# N32G032 register map
Vendor: Nationstech Ltd.; File version: 1.0
Registers are 32-bit, read-write, reset 0x0 unless marked. A register's access mark holds for its fields unless they carry their own. Offsets are from the block's base; [hi:lo] are bit positions; {n}, {i} and the like mark numbered series.

## EXTI — external interrupt/event controller
Base 0x40010400
0x00 EXTI_IMASK
  [23:0] IMASK
0x04 EXTI_EMASK
  [23:0] EMASK
0x08 EXTI_RT_CFG
  [23:0] RT_CFG
0x0C EXTI_FT_CFG
  [23:0] FT_CFG
0x10 EXTI_SWIE
  [23:0] SWIE
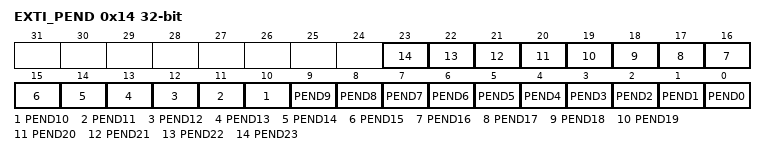
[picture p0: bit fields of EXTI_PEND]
0x14 EXTI_PEND
  [n] PEND{n} (n=0..23)
0x18 EXTI_TS_SEL
  [3:0] TSSEL

## FLASH — interal FLASH controller
Base 0x40022000
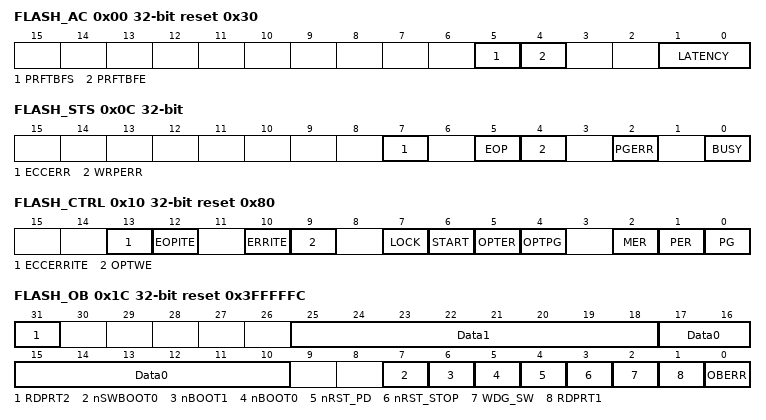
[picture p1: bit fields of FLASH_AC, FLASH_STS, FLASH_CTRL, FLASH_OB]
0x00 FLASH_AC reset 0x30
  [5] PRFTBFS, [4] PRFTBFE, [1:0] LATENCY
0x04 FLASH_KEY
  [31:0] FKEY
0x08 FLASH_OPTKEY
0x0C FLASH_STS
  [7] ECCERR, [5] EOP, [4] WRPERR, [2] PGERR, [0] BUSY
0x10 FLASH_CTRL reset 0x80
  [13] ECCERRITE, [12] EOPITE, [10] ERRITE, [9] OPTWE, [7] LOCK, [6] START, [5] OPTER, [4] OPTPG, [2] MER, [1] PER, [0] PG
0x14 FLASH_ADD
  [31:0] FADD
0x1C FLASH_OB reset 0x3FFFFFC
  [31] RDPRT2, [25:18] Data1, [17:10] Data0, [7] nSWBOOT0, [6] nBOOT1, [5] nBOOT0, [4] nRST_PD, [3] nRST_STOP, [2] WDG_SW, [1] RDPRT1, [0] OBERR
0x20 FLASH_WRP reset 0xFFFF (reset mask 0xFFFF)
  [31:0] WRPT
0x24 FLASH_ECC
  [5:0] ECC

## GPIOA — General purpose I/O
Base 0x40010800
Same registers: GPIOB 0x40010C00, GPIOC 0x40011000, GPIOD 0x40011400, GPIOF 0x40011C00
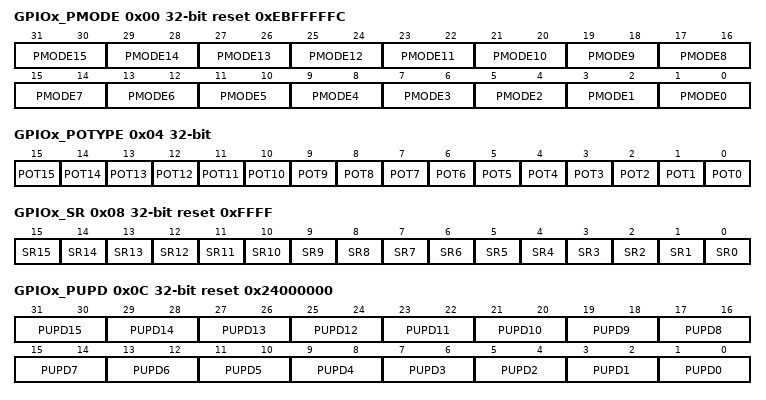
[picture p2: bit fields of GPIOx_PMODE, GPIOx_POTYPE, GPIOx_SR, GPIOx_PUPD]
0x00 GPIOx_PMODE reset 0xEBFFFFFC
  [2n+1:2n] PMODE{n} (n=0..15)
0x04 GPIOx_POTYPE
  [n] POT{n} (n=0..15)
0x08 GPIOx_SR reset 0xFFFF
  [n] SR{n} (n=0..15)
0x0C GPIOx_PUPD reset 0x24000000
  [2n+1:2n] PUPD{n} (n=0..15)
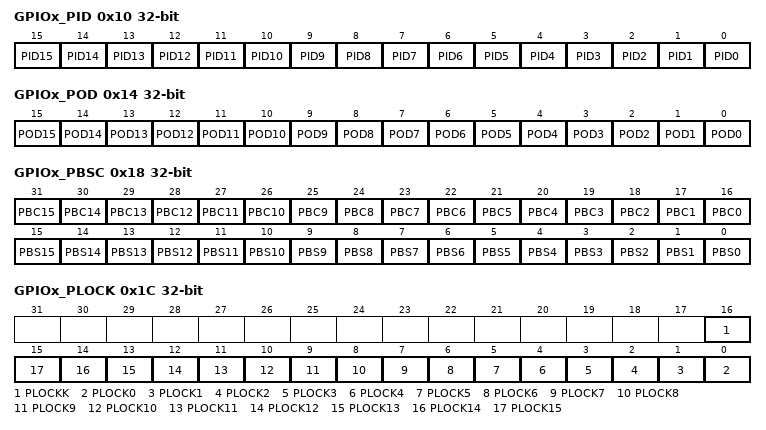
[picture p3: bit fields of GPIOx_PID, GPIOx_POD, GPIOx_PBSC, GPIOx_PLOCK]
0x10 GPIOx_PID
  [n] PID{n} (n=0..15)
0x14 GPIOx_POD
  [n] POD{n} (n=0..15)
0x18 GPIOx_PBSC
  [n+16] PBC{n} (n=0..15), [n] PBS{n} (n=0..15)
0x1C GPIOx_PLOCK
  [16] PLOCKK, [n] PLOCK{n} (n=0..15)
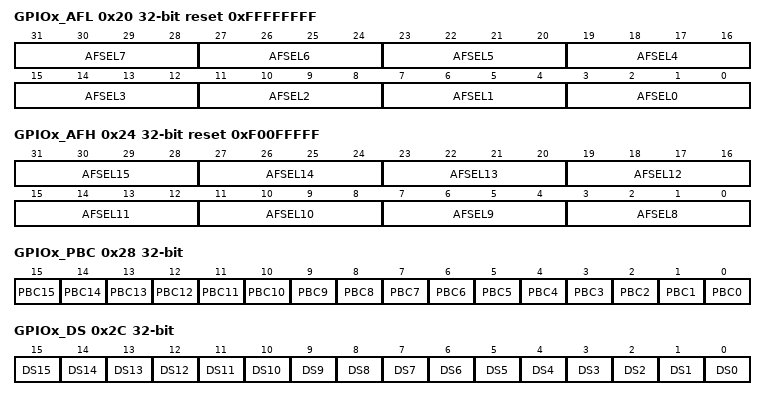
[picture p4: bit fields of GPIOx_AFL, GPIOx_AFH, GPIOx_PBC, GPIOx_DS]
0x20 GPIOx_AFL reset 0xFFFFFFFF
  [4n+3:4n] AFSEL{n} (n=0..7)
0x24 GPIOx_AFH reset 0xF00FFFFF
  [4n-29:4n-32] AFSEL{n} (n=8..15)
0x28 GPIOx_PBC
  [n] PBC{n} (n=0..15)
0x2C GPIOx_DS
  [n] DS{n} (n=0..15)

## AFIO — Alternate function I/O
Base 0x40010000
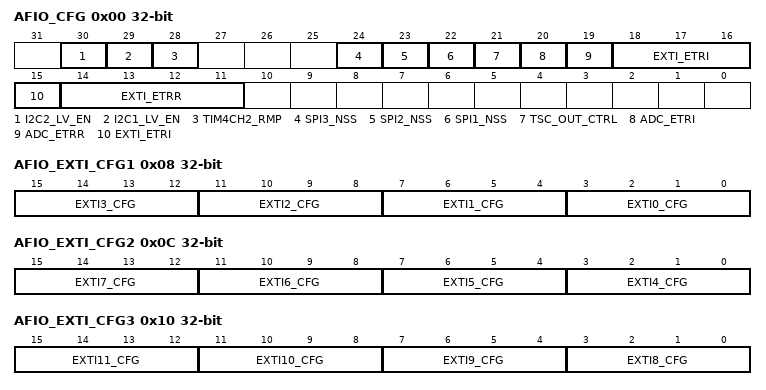
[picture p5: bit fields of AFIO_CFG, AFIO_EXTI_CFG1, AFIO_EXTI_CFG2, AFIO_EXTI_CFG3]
0x00 AFIO_CFG
  [30] I2C2_LV_EN
  [29] I2C1_LV_EN
  [28] TIM4CH2_RMP
  [24] SPI3_NSS
  [23] SPI2_NSS — SPI1_NSS
  [22] SPI1_NSS
  [21] TSC_OUT_CTRL
  [20] ADC_ETRI
  [19] ADC_ETRR
  [18:15] EXTI_ETRI
  [14:11] EXTI_ETRR
0x08 AFIO_EXTI_CFG1
  [4n+3:4n] EXTI{n}_CFG (n=0..3)
0x0C AFIO_EXTI_CFG2
  [4n-13:4n-16] EXTI{n}_CFG (n=4..7)
0x10 AFIO_EXTI_CFG3
  [4n-29:4n-32] EXTI{n}_CFG (n=8..11)
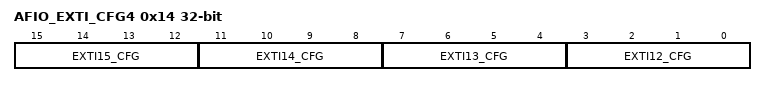
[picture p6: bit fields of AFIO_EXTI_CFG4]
0x14 AFIO_EXTI_CFG4
  [4n-45:4n-48] EXTI{n}_CFG (n=12..15)

## HDIV — High-speed divider
Base 0x40028000
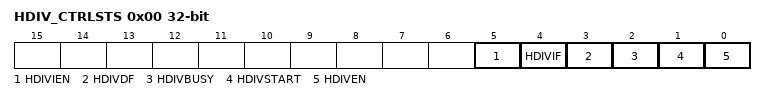
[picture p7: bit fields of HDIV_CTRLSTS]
0x00 HDIV_CTRLSTS
  [5] HDIVIEN, [4] HDIVIF, [3] HDIVDF, [2] HDIVBUSY, [1] HDIVSTART, [0] HDIVEN
0x04 HDIV_DIVIDEND
0x08 HDIV_DIVISOR
0x0C HDIV_QUOTIENT
0x10 HDIV_REMAINDER
0x14 HDIV_DIVBY0
  [0] DIVBY0

## I2C1 — Inter integrated circuit
Base 0x40005400
Same registers: I2C2 0x40005800
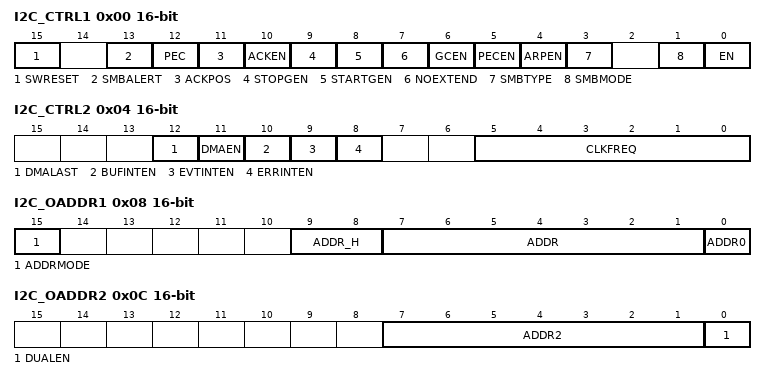
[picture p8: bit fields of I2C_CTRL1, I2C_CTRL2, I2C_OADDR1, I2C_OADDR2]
0x00 I2C_CTRL1 16-bit
  [15] SWRESET, [13] SMBALERT, [12] PEC, [11] ACKPOS, [10] ACKEN, [9] STOPGEN, [8] STARTGEN, [7] NOEXTEND, [6] GCEN, [5] PECEN, [4] ARPEN, [3] SMBTYPE, [1] SMBMODE, [0] EN
0x04 I2C_CTRL2 16-bit
  [12] DMALAST, [11] DMAEN, [10] BUFINTEN, [9] EVTINTEN, [8] ERRINTEN, [5:0] CLKFREQ
0x08 I2C_OADDR1 16-bit
  [15] ADDRMODE, [9:8] ADDR_H, [7:1] ADDR, [0] ADDR0
0x0C I2C_OADDR2 16-bit
  [7:1] ADDR2, [0] DUALEN
0x10 I2C_DAT 16-bit
  [7:0] DATA
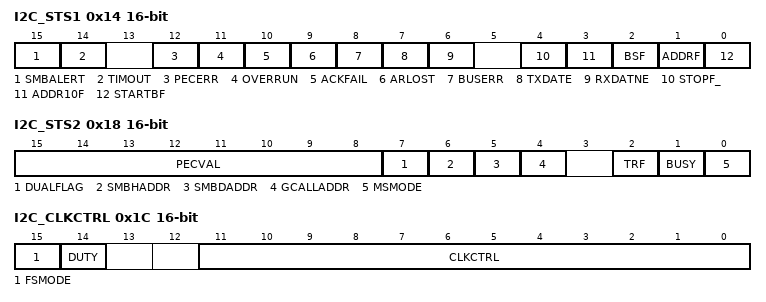
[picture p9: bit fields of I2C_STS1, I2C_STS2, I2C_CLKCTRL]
0x14 I2C_STS1 16-bit
  [15] SMBALERT, [14] TIMOUT, [12] PECERR, [11] OVERRUN, [10] ACKFAIL, [9] ARLOST, [8] BUSERR, [7] TXDATE, [6] RXDATNE, [4] STOPF_, [3] ADDR10F, [2] BSF, [1] ADDRF, [0] STARTBF
0x18 I2C_STS2 16-bit
  [15:8] PECVAL, [7] DUALFLAG, [6] SMBHADDR, [5] SMBDADDR, [4] GCALLADDR, [2] TRF, [1] BUSY, [0] MSMODE
0x1C I2C_CLKCTRL 16-bit
  [15] FSMODE, [14] DUTY, [11:0] CLKCTRL
0x20 I2C_TMRISE 16-bit
  [5:0] TMRISE

## IWDG — Independent watchdog
Base 0x40003000
0x00 IWDG_KEY
  [15:0] KEYV
0x04 IWDG_PREDIV
  [2:0] PD
0x08 IWDG_RELV reset 0xFFF
  [11:0] REL
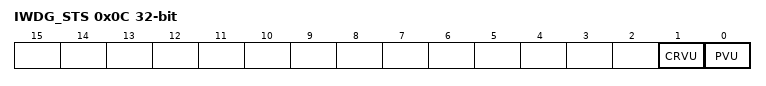
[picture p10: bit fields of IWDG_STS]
0x0C IWDG_STS
  [1] CRVU, [0] PVU
